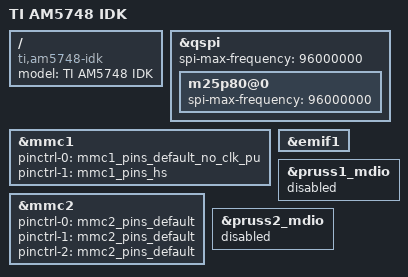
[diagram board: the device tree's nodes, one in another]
// SPDX-License-Identifier: GPL-2.0
/*
 * Copyright (C) 2017 Texas Instruments Incorporated - https://www.ti.com/
 */


/dts-v1/;

#include "am5748.dtsi"
#include "dra7-mmc-iodelay.dtsi"
#include "dra76x-mmc-iodelay.dtsi"
#include "am572x-idk-common.dtsi"

/ {
	model = "TI AM5748 IDK";
	compatible = "ti,am5748-idk", "ti,am5748", "ti,dra762", "ti,dra7";
};

&qspi {
	spi-max-frequency = <96000000>;
	m25p80@0 {
		spi-max-frequency = <96000000>;
	};
};

&mmc1 {
	pinctrl-names = "default", "hs";
	pinctrl-0 = <&mmc1_pins_default_no_clk_pu>;
	pinctrl-1 = <&mmc1_pins_hs>;
};

&mmc2 {
	pinctrl-names = "default", "hs", "ddr_3_3v";
	pinctrl-0 = <&mmc2_pins_default>;
	pinctrl-1 = <&mmc2_pins_default>;
	pinctrl-2 = <&mmc2_pins_default>;
};

&emif1 {
	status = "okay";
};

&pruss1_mdio {
	status = "disabled";
};

&pruss2_mdio {
	status = "disabled";
};
